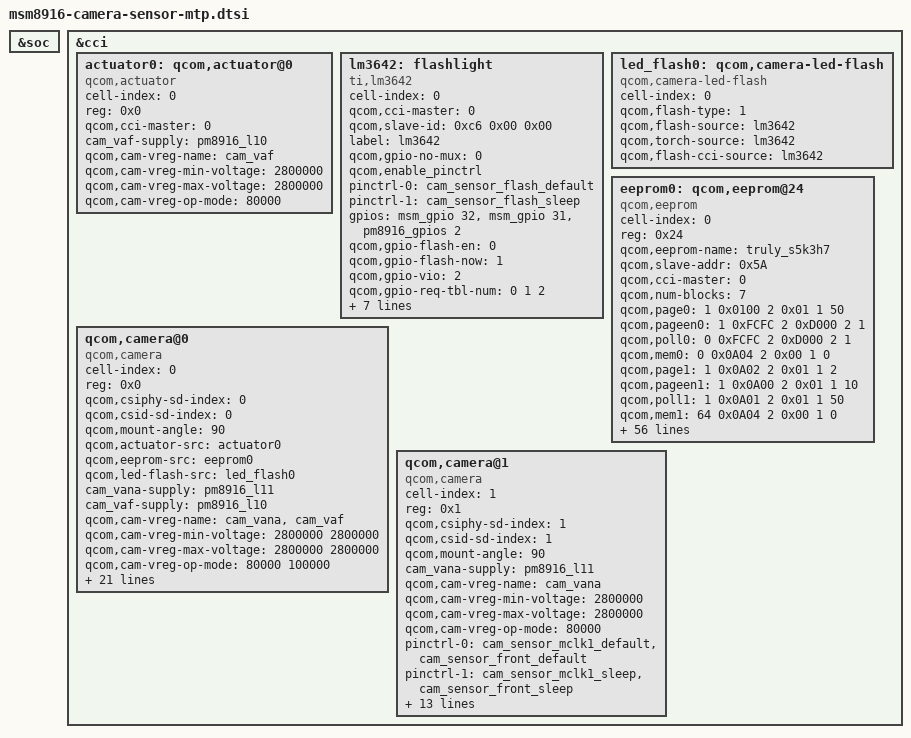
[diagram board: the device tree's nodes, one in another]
/*
 * Copyright (c) 2014, The Linux Foundation. All rights reserved.
 *
 * This program is free software; you can redistribute it and/or modify
 * it under the terms of the GNU General Public License version 2 and
 * only version 2 as published by the Free Software Foundation.
 *
 * This program is distributed in the hope that it will be useful,
 * but WITHOUT ANY WARRANTY; without even the implied warranty of
 * MERCHANTABILITY or FITNESS FOR A PARTICULAR PURPOSE.  See the
 * GNU General Public License for more details.
 */

&soc {
};

&cci {

	actuator0: qcom,actuator@0 {
		cell-index = <0>;
		reg = <0x0>;
		compatible = "qcom,actuator";
		qcom,cci-master = <0>;
		cam_vaf-supply = <&pm8916_l10>;
		qcom,cam-vreg-name = "cam_vaf";
		qcom,cam-vreg-min-voltage = <2800000>;
		qcom,cam-vreg-max-voltage = <2800000>;
		qcom,cam-vreg-op-mode = <80000>;
	};

	lm3642:flashlight {
		cell-index = <0>;
		compatible = "ti,lm3642";
		status = "okay";
		qcom,cci-master = <0>;
		qcom,slave-id = <0xc6 0x00 0x00>;
		label = "lm3642";
		qcom,gpio-no-mux = <0>;
		qcom,enable_pinctrl;
		pinctrl-names = "cam_flash_default", "cam_flash_suspend";
		pinctrl-0 = <&cam_sensor_flash_default>;
		pinctrl-1 = <&cam_sensor_flash_sleep>;
		gpios = <&msm_gpio 32 0>,<&msm_gpio 31 0>,<&pm8916_gpios 2 0>;
		qcom,gpio-flash-en = <0>;
		qcom,gpio-flash-now = <1>;
		qcom,gpio-vio = <2>;
		qcom,gpio-req-tbl-num = <0 1 2>;
		qcom,gpio-req-tbl-flags = <0 0 0>;
		qcom,gpio-req-tbl-label = "FLASH_EN", "FLASH_NOW", "Gpio-vio";
		qcom,current = <200>;
		qcom,max-current = <950>;
		linux,name = "flashlight";
		linux,default-trigger = "flashlight-trigger";
	};

	led_flash0: qcom,camera-led-flash {
		cell-index = <0>;
		compatible = "qcom,camera-led-flash";
		qcom,flash-type = <1>;
		qcom,flash-source = <&lm3642>;
		qcom,torch-source = <&lm3642>;
		qcom,flash-cci-source = <&lm3642>;
	};

	eeprom0: qcom,eeprom@24 {
		cell-index = <0>;
		reg = <0x24>;
		qcom,eeprom-name = "truly_s5k3h7";
		compatible = "qcom,eeprom";
		qcom,slave-addr = <0x5A>;
		qcom,cci-master = <0>;

		qcom,num-blocks = <7>;

		qcom,page0 =   <1 0x0100 2 0x01 1 50>;
		qcom,pageen0 = <1 0xFCFC 2 0xD000 2 1>;
		qcom,poll0 =   <0 0xFCFC 2 0xD000 2 1>;
		qcom,mem0 =   <0 0x0A04 2 0x00 1 0>;

		qcom,page1 =   <1 0x0A02 2 0x01 1 2>;
		qcom,pageen1 = <1 0x0A00 2 0x01 1 10>;
		qcom,poll1 =   <1 0x0A01 2 0x01 1 50>;
		qcom,mem1 =   <64 0x0A04 2 0x00 1 0>;

		qcom,page2 =   <1 0x0A00 2 0x00 1 1>;
		qcom,pageen2 = <0 0x0A02 2 0x02 1 20>;
		qcom,poll2 =   <0 0x0A00 2 0x01 1 1>;
		qcom,mem2 =   <0 0x0A04 2 0x00 1 0>;

		qcom,page3 =   <1 0x0A02 2 0x02 1 2>;
		qcom,pageen3 = <1 0x0A00 2 0x01 1 10>;
		qcom,poll3 =   <1 0x0A01 2 0x01 1 50>;
		qcom,mem3 =   <64 0x0A04 2 0x00 1 0>;

		qcom,page4 =   <1 0x0A00 2 0x00 1 2>;
		qcom,pageen4 = <0 0x0A00 2 0x01 1 1>;
		qcom,poll4 =   <0 0x0A01 2 0x01 1 50>;
		qcom,mem4 =   <0 0x0A04 2 0x00 1 0>;

		qcom,page5 =   <1 0x0A02 2 0x03 1 2>;
		qcom,pageen5 = <1 0x0A00 2 0x01 1 10>;
		qcom,poll5 =   <1 0x0A01 2 0x01 1 50>;
		qcom,mem5 =   <64 0x0A04 2 0x00 1 0>;

		qcom,page6 =   <1 0x0A00 2 0x00 1 2>;
		qcom,pageen6 = <0 0x0A00 2 0x01 1 1>;
		qcom,poll6 =   <0 0x0A01 2 0x01 1 1>;
		qcom,mem6 =   <0 0x0A04 2 0x00 1 0>;

		cam_vana-supply = <&pm8916_l11>;
		qcom,cam-vreg-name = "cam_vdig", "cam_vio", "cam_vana";
		qcom,cam-vreg-type = <0 0 0>;
		qcom,cam-vreg-min-voltage = <0 0 2800000>;
		qcom,cam-vreg-max-voltage = <0 0 2800000>;
		qcom,cam-vreg-op-mode = <0  0 100000>;
		pinctrl-names = "cam_default", "cam_suspend";
		pinctrl-0 = <&cam_sensor_mclk0_default
				&cam_sensor_rear_default>;
		pinctrl-1 = <&cam_sensor_mclk0_sleep &cam_sensor_rear_sleep>;
		gpios = <&msm_gpio 26 0>,
			<&msm_gpio 35 0>,
			<&msm_gpio 20 0>,
			<&msm_gpio 34 0>,
			<&pm8916_gpios 2 0>;
		qcom,gpio-reset = <1>;
		qcom,gpio-standby = <2>;
		qcom,gpio-vdig = <3>;
		qcom,gpio-vio = <4>;
		qcom,gpio-req-tbl-num = <0 1 2 3 4>;
		qcom,gpio-req-tbl-flags = <1 0 0 0 0>;
		qcom,gpio-req-tbl-label = "CAMIF_MCLK0",
			"CAM_RESET0",
			"CAM_STANDBY0",
			"CAM_DVIG0",
			"CAM_VDDIO0";

		qcom,gpio-set-tbl-delay = <1000 4000>;
		qcom,csi-lane-assign = <0x4320>;
		qcom,csi-lane-mask = <0x1f>;
		qcom,cam-power-seq-type = "sensor_gpio", "sensor_vreg", "sensor_gpio",
			"sensor_gpio", "sensor_clk";
		qcom,cam-power-seq-val = "sensor_gpio_vio", "cam_vana", "sensor_gpio_vdig",
			"sensor_gpio_reset","sensor_cam_mclk";
		qcom,cam-power-seq-cfg-val = <1 1 1 1 23880000>;
		qcom,cam-power-seq-delay = <10 10 5 10 5>;

		qcom,mclk-23880000;
		status = "ok";
		clocks = <&clock_gcc clk_mclk0_clk_src>,
				<&clock_gcc clk_gcc_camss_mclk0_clk>;
		clock-names = "cam_src_clk", "cam_clk";
	};

	qcom,camera@0 {
		cell-index = <0>;
		compatible = "qcom,camera";
		reg = <0x0>;
		qcom,csiphy-sd-index = <0>;
		qcom,csid-sd-index = <0>;
		qcom,mount-angle = <90>;
		qcom,actuator-src = <&actuator0>;
		qcom,eeprom-src = <&eeprom0>;
		qcom,led-flash-src = <&led_flash0>;
		cam_vana-supply = <&pm8916_l11>;
		cam_vaf-supply = <&pm8916_l10>;
		qcom,cam-vreg-name = "cam_vana", "cam_vaf";
		qcom,cam-vreg-min-voltage = <2800000 2800000>;
		qcom,cam-vreg-max-voltage = <2800000 2800000>;
		qcom,cam-vreg-op-mode = <80000 100000>;
		pinctrl-names = "cam_default", "cam_suspend";
		pinctrl-0 = <&cam_sensor_mclk0_default
				&cam_sensor_rear_default>;
		pinctrl-1 = <&cam_sensor_mclk0_sleep &cam_sensor_rear_sleep>;
		gpios = <&msm_gpio 26 0>,
			<&msm_gpio 35 0>,
			<&msm_gpio 20 0>,
			<&msm_gpio 34 0>,
			<&pm8916_gpios 2 0>;
		qcom,gpio-reset = <1>;
		qcom,gpio-standby = <2>;
		qcom,gpio-vdig = <3>;
		qcom,gpio-vio = <4>;
		qcom,gpio-req-tbl-num = <0 1 2 3 4>;
		qcom,gpio-req-tbl-flags = <1 0 0 0 0>;
		qcom,gpio-req-tbl-label = "CAMIF_MCLK0",
			"CAM_RESET0",
			"CAM_STANDBY0",
			"CAM_DVIG0",
			"CAM_VDDIO0";
		qcom,sensor-position = <0>;
		qcom,sensor-mode = <0>;
		qcom,cci-master = <0>;
		qcom,mclk-23880000;
		status = "ok";
		clocks = <&clock_gcc clk_mclk0_clk_src>,
				<&clock_gcc clk_gcc_camss_mclk0_clk>;
		clock-names = "cam_src_clk", "cam_clk";
	};

	qcom,camera@1 {
		cell-index = <1>;
		compatible = "qcom,camera";
		reg = <0x1>;
		qcom,csiphy-sd-index = <1>;
		qcom,csid-sd-index = <1>;
		qcom,mount-angle = <90>;
		cam_vana-supply = <&pm8916_l11>;
		qcom,cam-vreg-name = "cam_vana";
		qcom,cam-vreg-min-voltage = <2800000>;
		qcom,cam-vreg-max-voltage = <2800000>;
		qcom,cam-vreg-op-mode = <80000>;
		pinctrl-names = "cam_default", "cam_suspend";
		pinctrl-0 = <&cam_sensor_mclk1_default &cam_sensor_front_default>;
		pinctrl-1 = <&cam_sensor_mclk1_sleep &cam_sensor_front_sleep>;
		gpios = <&msm_gpio 27 0>,
			<&msm_gpio 28 0>,
			<&msm_gpio 33 0>,
			<&pm8916_gpios 2 0>;
		qcom,gpio-reset = <1>;
		qcom,gpio-standby = <2>;
		qcom,gpio-vio = <3>;
		qcom,gpio-req-tbl-num = <0 1 2 3>;
		qcom,gpio-req-tbl-flags = <1 0 0 0>;
		qcom,gpio-req-tbl-label = "CAMIF_MCLK",
			"CAM_RESET1",
			"CAM_STANDBY1",
			"CAM_VDDIO1";
		qcom,cci-master = <0>;
		qcom,mclk-23880000;
		status = "ok";
		clocks = <&clock_gcc clk_mclk1_clk_src>,
				<&clock_gcc clk_gcc_camss_mclk1_clk>;
		clock-names = "cam_src_clk", "cam_clk";
	};
};
